# Z32F3841 register map
Vendor: Zilog, Inc; File version: 1.0.1
CPU: CM3 r2p0, little endian, no MPU, no FPU, 3 interrupt priority bits
Registers are 32-bit, read-write, reset 0x0 unless marked. A register's access mark holds for its fields unless they carry their own. Offsets are from the block's base; [hi:lo] are bit positions; {n}, {i} and the like mark numbered series.

## WDT — WATCH-DOG TIMER
Base 0x40000200
0x00 LR — Watchdog Timer Load Register
0x04 CNT reset 0xFFFF — Watchdog Timer Current Counter Register
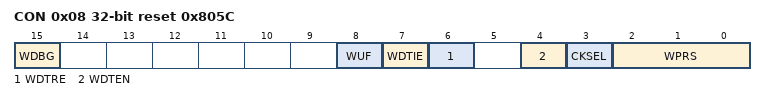
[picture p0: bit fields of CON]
0x08 CON reset 0x805C — Watchdog Timer Control Register
  [15] WDBG — WDT operation in debug mode
  [8] WUF — WDT underflow falg
  [7] WDTIE — WDT interrupt enable
  [6] WDTRE — WDT interrupt reset
  [4] WDTEN — WDT counter enable
  [3] CKSEL — WDTCLKIN clock source select
  [2:0] WPRS — counter prescaler

## DC0 — DIRECT MEMORY ACCESS CONTROLLER
Base 0x40000400
Same registers: DC1 0x40000410, DC2 0x40000420, DC3 0x40000430, DC4 0x40000440, DC5 0x40000450, DC6 0x40000460, DC7 0x40000470
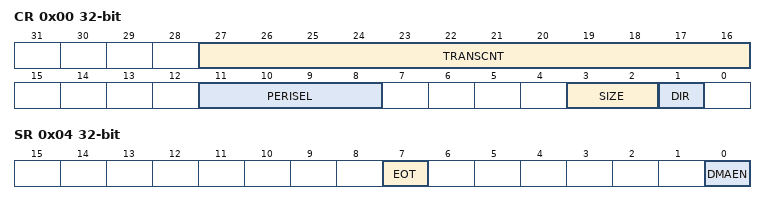
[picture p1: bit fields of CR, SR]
0x00 CR — DMA Controller Configuration Register
  [27:16] TRANSCNT — Numer of DMA transfer remained
  [11:8] PERISEL — Peripheral selection
  [3:2] SIZE — Bus transfer size
  [1] DIR — Select Direction of Transfer
0x04 SR — DMA Controller Status register
  [7] EOT ro — End of transfer
  [0] DMAEN — DMA enable
0x08 PAR — DMA Controller Peripheral Address register
  [15:0] PAR — Periphreal address
0x0C MAR reset 0x20000000 — DMA Controller Memory Address register
  [15:0] MAR — Memory address

## PCA — PORT CONTROL UNIT
Base 0x40001000
Same registers: PCB 0x40001100, PCC 0x40001200, PCD 0x40001300, PCE 0x40001400, PCF 0x40001500
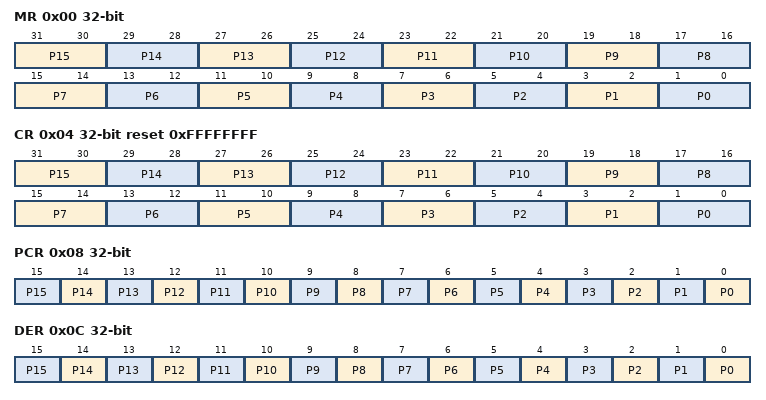
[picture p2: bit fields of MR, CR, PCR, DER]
0x00 MR — PORT n Pin MUX Register
  [31:30] P15 — P15 Pin Mux select
  [29:28] P14 — P14 MUX SEL
  [27:26] P13 — P13 Pin Mux select
  [25:24] P12 — P12 MUX SEL
  [23:22] P11 — P11 Pin Mux select
  [21:20] P10 — P10 MUX SEL
  [19:18] P9 — P9 Pin Mux select
  [17:16] P8 — P8 MUX SEL
  [15:14] P7 — P7 Pin Mux select
  [13:12] P6 — P6 MUX SEL
  [11:10] P5 — P5 Pin Mux select
  [9:8] P4 — P4 MUX SEL
  [7:6] P3 — P3 Pin Mux select
  [5:4] P2 — P2 MUX SEL
  [3:2] P1 — P1 Pin Mux select
  [1:0] P0 — P0 MUX SEL
0x04 CR reset 0xFFFFFFFF — PORT n Pin Control Register
  [31:30] P15 — P15 control select
  [29:28] P14 — P14 control SEL
  [27:26] P13 — P13 control select
  [25:24] P12 — P12 control SEL
  [23:22] P11 — P11 control select
  [21:20] P10 — P10 control SEL
  [19:18] P9 — P9 control select
  [17:16] P8 — P8 control SEL
  [15:14] P7 — P7 control select
  [13:12] P6 — P6 control SEL
  [11:10] P5 — P5 control select
  [9:8] P4 — P4 control SEL
  [7:6] P3 — P3 control select
  [5:4] P2 — P2 control SEL
  [3:2] P1 — P1 control select
  [1:0] P0 — P0 control SEL
0x08 PCR — PORT n Pull-up Resistor Control Register
  [n] P{n} (n=0..15) — P{n} pull-up enable
0x0C DER — PORT n Debounce Enable Register
  [n] P{n} (n=0..15) — P{n} Debounce enable
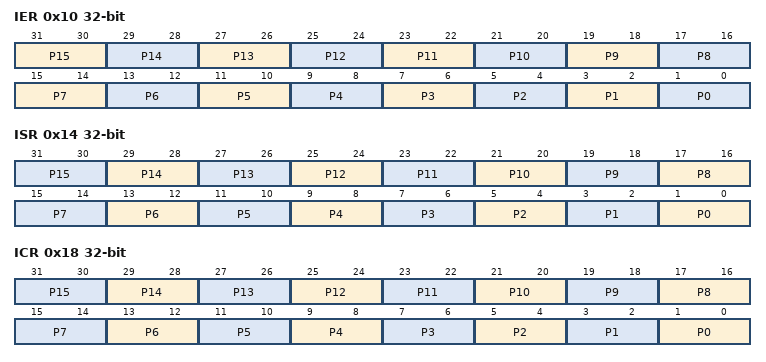
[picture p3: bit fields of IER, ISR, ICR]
0x10 IER — PORT n Interrupt Enable Register
  [31:30] P15 — P15 interrupt select
  [29:28] P14 — P14 interrupt SEL
  [27:26] P13 — P13 interrupt select
  [25:24] P12 — P12 interrupt SEL
  [23:22] P11 — P11 interrupt select
  [21:20] P10 — P10 interrupt SEL
  [19:18] P9 — P9 interrupt select
  [17:16] P8 — P8 interrupt SEL
  [15:14] P7 — P7 interrupt select
  [13:12] P6 — P6 interrupt SEL
  [11:10] P5 — P5 interrupt select
  [9:8] P4 — P4 interrupt SEL
  [7:6] P3 — P3 interrupt select
  [5:4] P2 — P2 interrupt SEL
  [3:2] P1 — P1 interrupt select
  [1:0] P0 — P0 interrupt enable
0x14 ISR — PORT n Interrupt Status Register
  [2n+1:2n] P{n} (n=0..15) — P{n} interrupt status
0x18 ICR — PORT n Interrupt Control Register
  [2n+1:2n] P{n} (n=0..15) — P{n} interrupt control

## PORTEN — Port Access Eable
Base 0x40001FF0
0x00 EN (reset mask 0xFFFF) — Port Access Enable

## PA — GENERAL PURPOSE I/O
Base 0x40002000
Same registers: PB 0x40002100, PC 0x40002200, PD 0x40002300, PE 0x40002400, PF 0x40002500
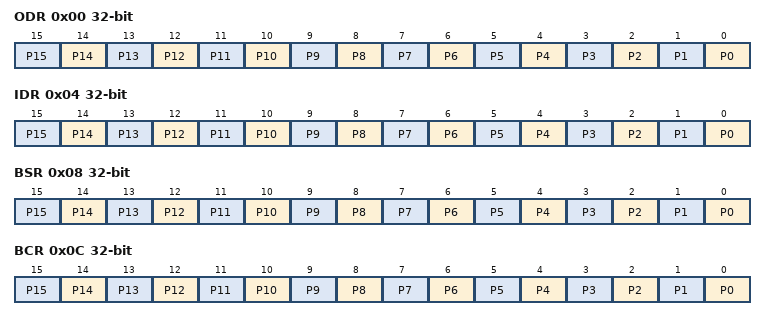
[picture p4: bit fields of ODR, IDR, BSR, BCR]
0x00 ODR — PORT n Output Data Register
  [n] P{n} (n=0..15) — P{n} Output level
0x04 IDR ro — PORT n Input Data Register
  [n] P{n} (n=0..15) — P{n} Input level
0x08 BSR wo — PORT n Bit Set Register
  [n] P{n} (n=0..15) — P{n} bit set
0x0C BCR wo — PORT n Bit Clear Register
  [n] P{n} (n=0..15) — P{n} bit clear
